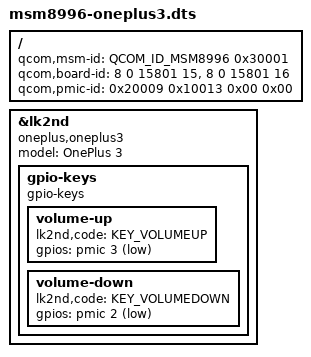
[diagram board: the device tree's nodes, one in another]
// SPDX-License-Identifier: BSD-3-Clause

#include <skeleton64.dtsi>
#include <lk2nd.dtsi>

/ {
	qcom,msm-id = <QCOM_ID_MSM8996 0x30001>;
	qcom,board-id = <8 0 15801 15>, <8 0 15801 16>;
	qcom,pmic-id = <0x20009 0x10013 0x00 0x00>;
};

&lk2nd {
	model = "OnePlus 3";
	compatible = "oneplus,oneplus3";

	gpio-keys {
		compatible = "gpio-keys";

		volume-up {
			lk2nd,code = <KEY_VOLUMEUP>;
			gpios = <&pmic 3 GPIO_ACTIVE_LOW>;
		};

		volume-down {
			lk2nd,code = <KEY_VOLUMEDOWN>;
			gpios = <&pmic 2 GPIO_ACTIVE_LOW>;
		};
	};
};
